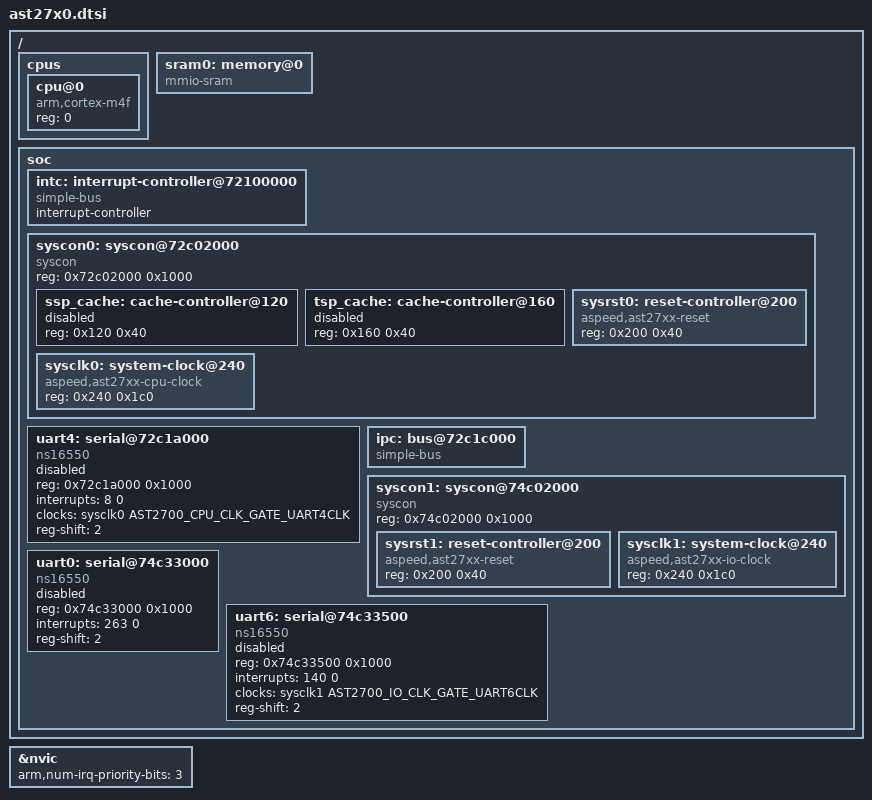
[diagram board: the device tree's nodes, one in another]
/*
 * SPDX-License-Identifier: Apache-2.0
 *
 * Copyright (c) 2023 ASPEED Technology Inc.
 */

#include <arm/armv7-m.dtsi>
#include <mem.h>
#include <zephyr/dt-bindings/clock/ast27xx_clock.h>

/ {
	cpus {
		#address-cells = <1>;
		#size-cells = <0>;

		cpu@0 {
			device_type = "cpu";
			compatible = "arm,cortex-m4f";
			reg = <0>;
		};
	};

	sram0: memory@0 {
		compatible = "mmio-sram";
	};

	soc {
		intc: interrupt-controller@72100000 {
			compatible = "simple-bus";
			interrupt-controller;
			#interrupt-cells = <1>;
			#address-cells = <1>;
			#size-cells = <1>;
			ranges = <0x0 0x72100000 0x4000>;
		};

		syscon0: syscon@72c02000 {
			compatible = "syscon";
			reg = <0x72c02000 0x1000>;
			#address-cells = <1>;
			#size-cells = <1>;

			ssp_cache: cache-controller@120 {
				reg = <0x120 0x40>;
				status = "disabled";
			};

			tsp_cache: cache-controller@160 {
				reg = <0x160 0x40>;
				status = "disabled";
			};

			sysrst0: reset-controller@200 {
				compatible = "aspeed,ast27xx-reset";
				reg = <0x200 0x40>;
				#reset-cells = <1>;
			};

			sysclk0: system-clock@240 {
				compatible = "aspeed,ast27xx-cpu-clock";
				reg = <0x240 0x1c0>;
				#clock-cells = <1>;
				status = "okay";
			};
		};

		uart4: serial@72c1a000 {
			compatible = "ns16550";
			reg = <0x72c1a000 0x1000>;
			interrupts = <8 0>;
			clocks = <&sysclk0 AST2700_CPU_CLK_GATE_UART4CLK>;
			status = "disabled";
			reg-shift = <2>;
		};

		ipc: bus@72c1c000 {
			compatible = "simple-bus";
			#address-cells = <1>;
			#size-cells = <1>;
			ranges = <0 0x72c1c000 0x1000>;
		};

		syscon1: syscon@74c02000 {
			compatible = "syscon";
			reg = <0x74c02000 0x1000>;
			#address-cells = <1>;
			#size-cells = <1>;

			sysrst1: reset-controller@200 {
				compatible = "aspeed,ast27xx-reset";
				reg = <0x200 0x40>;
				#reset-cells = <1>;
			};

			sysclk1: system-clock@240 {
				compatible = "aspeed,ast27xx-io-clock";
				reg = <0x240 0x1c0>;
				#clock-cells = <1>;
			};
		};

		uart0: serial@74c33000 {
			compatible = "ns16550";
			reg = <0x74c33000 0x1000>;
			interrupts = <263 0>;
			status = "disabled";
			reg-shift = <2>;
		};

		uart6: serial@74c33500 {
			compatible = "ns16550";
			reg = <0x74c33500 0x1000>;
			interrupts = <140 0>;
			clocks = <&sysclk1 AST2700_IO_CLK_GATE_UART6CLK>;
			status = "disabled";
			reg-shift = <2>;
		};
	};
};

&nvic {
	arm,num-irq-priority-bits = <3>;
};
